# STM32H725 register map
File version: 2.0
CPU: CM7 r0p1, little endian, MPU, FPU, 4 interrupt priority bits
Registers are 32-bit, read-write, reset 0x0 unless marked. A register's access mark holds for its fields unless they carry their own. Offsets are from the block's base; [hi:lo] are bit positions; {n}, {i} and the like mark numbered series; 'fields as' and 'values as' point back to an identical list.

## HSEM
Base 0x58026400
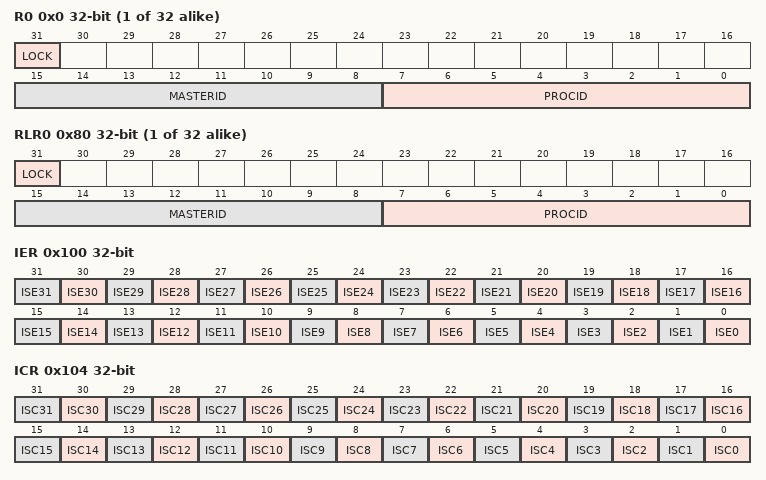
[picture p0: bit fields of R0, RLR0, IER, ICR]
{0x0+4i} R{i} (i=0..31) — HSEM register HSEM_R{i}
  [31] LOCK — Lock indication
    on read: 0=Free (Semaphore is free); 1=Locked (Semaphore is locked) | on write: 0=Free semaphore; 1=TryLock (Try to lock semaphore)
  [15:8] MASTERID range 0..15 — Semaphore MasterID
  [7:0] PROCID — Semaphore ProcessID
{0x80+4i} RLR{i} (i=0..31) ro — Semaphore {i} read lock register
  [31] LOCK — Lock indication
    0=Free (Semaphore is free); 1=Locked (Semaphore is locked)
  [15:8] MASTERID range 0..15 — Semaphore MasterID
  [7:0] PROCID — Semaphore ProcessID
0x100 IER — HSEM Interrupt enable register
  [n] ISE{n} (n=0..31) — Interrupt semaphore {n} enable bit
    0=Disabled (Interrupt generation disabled); 1=Enabled (Interrupt generation enabled)
0x104 ICR — HSEM Interrupt clear register
  [n] ISC{n} (n=0..31) — Interrupt semaphore {n} clear bit
    on read: 0=NoEffect (Always reads 0) | on write: 0=NoEffect (Interrupt semaphore x status ISFx and masked status MISFx not affected); 1=Clear (Interrupt semaphore x status ISFx and masked status MISFx cleared)
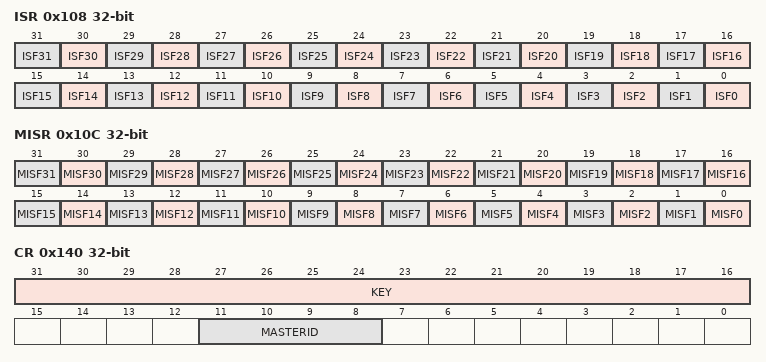
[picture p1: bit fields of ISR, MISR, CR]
0x108 ISR ro — HSEM Interrupt status register
  [n] ISF{n} (n=0..31) — Interrupt semaphore {n} status bit before enable (mask)
    0=NotPending (No interrupt pending); 1=Pending (Interrupt pending)
0x10C MISR ro — HSEM Masked interrupt status register
  [n] MISF{n} (n=0..31) — Masked interrupt semaphore {n} status bit after enable (mask)
    0=NotPending (No interrupt pending after masking); 1=Pending (Interrupt pending after masking)
0x140 CR — HSEM Clear register
  [31:16] KEY — Semaphore clear Key
  [11:8] MASTERID — MasterID of semaphores to be cleared
0x144 KEYR — HSEM Interrupt clear register
  [31:16] KEY — Semaphore Clear Key

## MDIOS — Management data input/output slave
Base 0x40009400
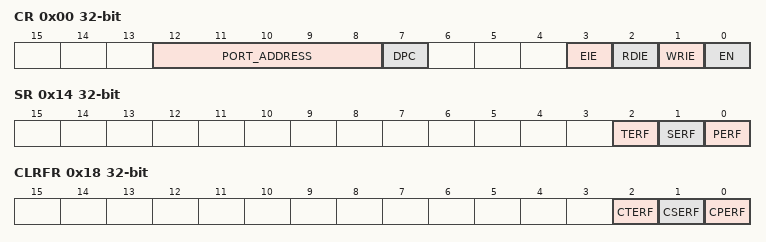
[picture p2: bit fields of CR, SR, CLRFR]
0x00 CR — MDIOS configuration register
  [12:8] PORT_ADDRESS — Slaves's address
  [7] DPC — Disable Preamble Check
  [3] EIE — Error interrupt enable
  [2] RDIE — Register Read Interrupt Enable
  [1] WRIE — Register write interrupt enable
  [0] EN — Peripheral enable
0x04 WRFR ro — MDIOS write flag register
  [31:0] WRF — Write flags for MDIO registers 0 to 31
0x08 CWRFR — MDIOS clear write flag register
  [31:0] CWRF — Clear the write flag
0x0C RDFR ro — MDIOS read flag register
  [31:0] RDF — Read flags for MDIO registers 0 to 31
0x10 CRDFR — MDIOS clear read flag register
  [31:0] CRDF — Clear the read flag
0x14 SR ro — MDIOS status register
  [2] TERF — Turnaround error flag
  [1] SERF — Start error flag
  [0] PERF — Preamble error flag
0x18 CLRFR — MDIOS clear flag register
  [2] CTERF — Clear the turnaround error flag
  [1] CSERF — Clear the start error flag
  [0] CPERF — Clear the preamble error flag
{0x1C+4i} DINR{i} ro (i=0..31) — MDIOS input data register {i}
  [15:0] DIN{i} — Input data received from MDIO Master during write frames
{0x9C+4i} DOUTR{i} (i=0..31) — MDIOS output data register {i}
  [15:0] DOUT{i} — Output data sent to MDIO Master during read frames

## OPAMP — Operational amplifiers
Base 0x40009000
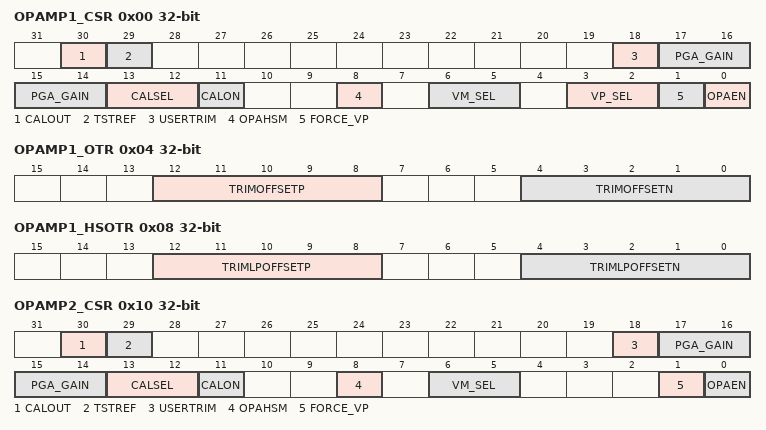
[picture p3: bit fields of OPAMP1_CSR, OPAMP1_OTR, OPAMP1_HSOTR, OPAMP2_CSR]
0x00 OPAMP1_CSR — OPAMP1 control/status register
  [30] CALOUT — Operational amplifier calibration output
  [29] TSTREF — OPAMP calibration reference voltage output control (reserved for test)
  [18] USERTRIM — User trimming enable
  [17:14] PGA_GAIN — allows to switch from AOP offset trimmed values to AOP offset
  [13:12] CALSEL — Calibration selection
  [11] CALON — Calibration mode enabled
  [8] OPAHSM — Operational amplifier high-speed mode
  [6:5] VM_SEL — Inverting input selection
  [3:2] VP_SEL — Operational amplifier PGA mode
  [1] FORCE_VP — Force internal reference on VP (reserved for test
  [0] OPAEN — Operational amplifier Enable
0x04 OPAMP1_OTR — OPAMP1 offset trimming register in normal mode
  [12:8] TRIMOFFSETP — Trim for PMOS differential pairs
  [4:0] TRIMOFFSETN — Trim for NMOS differential pairs
0x08 OPAMP1_HSOTR — OPAMP1 offset trimming register in low-power mode
  [12:8] TRIMLPOFFSETP — Trim for PMOS differential pairs
  [4:0] TRIMLPOFFSETN — Trim for NMOS differential pairs
0x10 OPAMP2_CSR — OPAMP2 control/status register
  [30] CALOUT — Operational amplifier calibration output
  [29] TSTREF — OPAMP calibration reference voltage output control (reserved for test)
  [18] USERTRIM — User trimming enable
  [17:14] PGA_GAIN — Operational amplifier Programmable amplifier gain value
  [13:12] CALSEL — Calibration selection
  [11] CALON — Calibration mode enabled
  [8] OPAHSM — Operational amplifier high-speed mode
  [6:5] VM_SEL — Inverting input selection
  [1] FORCE_VP — Force internal reference on VP (reserved for test)
  [0] OPAEN — Operational amplifier Enable
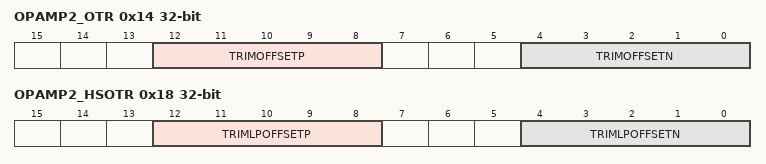
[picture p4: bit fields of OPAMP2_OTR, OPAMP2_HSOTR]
0x14 OPAMP2_OTR — OPAMP2 offset trimming register in normal mode
  fields as OPAMP1_OTR
0x18 OPAMP2_HSOTR — OPAMP2 offset trimming register in low-power mode
  fields as OPAMP1_HSOTR
